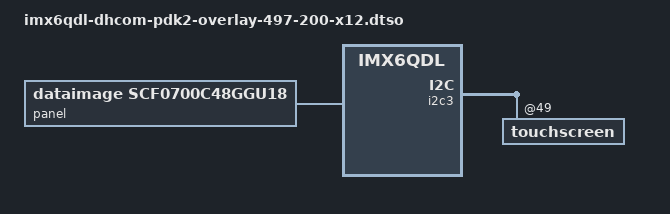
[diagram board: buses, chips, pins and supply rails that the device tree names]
// SPDX-License-Identifier: (GPL-2.0+ OR BSD-3-Clause)
/*
 * Copyright (C) 2021 Marek Vasut <marex@denx.de>
 * Copyright (C) 2023 DH electronics GmbH
 */
/dts-v1/;
/plugin/;

#include "imx6qdl-dhcom-overlay-panel-dpi.dtsi"

&display_bl {
	enable-gpios = <&gpio3 27 GPIO_ACTIVE_HIGH>; /* GPIO G */
	pwms = <&pwm1 0 50000 PWM_POLARITY_INVERTED>;
};

&panel {
	compatible = "dataimage,scf0700c48ggu18";
};

&i2c3 {
	touchscreen@49 { /* TSC2004 */
		status = "okay";
	};
};
